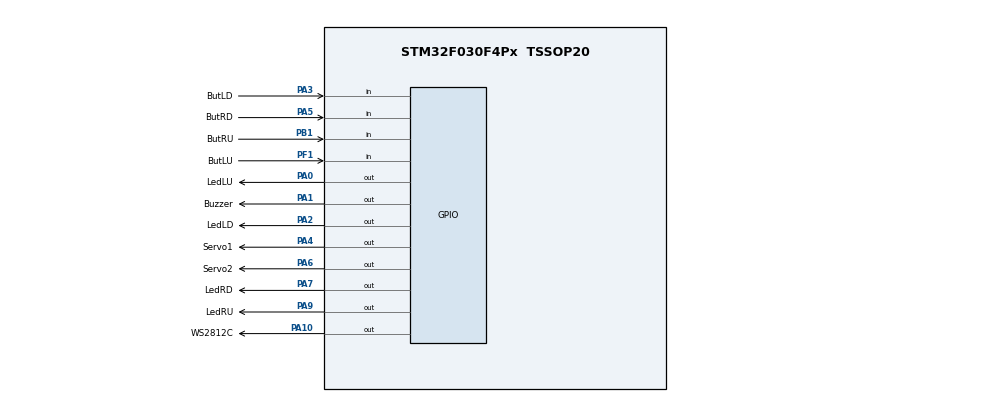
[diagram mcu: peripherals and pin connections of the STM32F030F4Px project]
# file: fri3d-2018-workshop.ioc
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Mcu.Family=STM32F0
Mcu.Name=STM32F030F4Px
Mcu.Package=TSSOP20
PA0.GPIO_Label=LedLU
PA0.Signal=GPIO_Output
PA1.GPIO_Label=Buzzer
PA1.Signal=GPIO_Output
PA10.GPIO_Label=WS2812C
PA10.Signal=GPIO_Output
PA13.Mode=Serial_Wire
PA13.Signal=SYS_SWDIO
PA14.Mode=Serial_Wire
PA14.Signal=SYS_SWCLK
PA2.GPIO_Label=LedLD
PA2.Signal=GPIO_Output
PA3.GPIO_Label=ButLD
PA3.GPIO_PuPd=GPIO_PULLUP
PA3.Signal=GPIO_Input
PA4.GPIO_Label=Servo1
PA4.Signal=GPIO_Output
PA5.GPIO_Label=ButRD
PA5.GPIO_PuPd=GPIO_PULLUP
PA5.Signal=GPIO_Input
PA6.GPIO_Label=Servo2
PA6.Signal=GPIO_Output
PA7.GPIO_Label=LedRD
PA7.Signal=GPIO_Output
PA9.GPIO_Label=LedRU
PA9.Signal=GPIO_Output
PB1.GPIO_Label=ButRU
PB1.GPIO_PuPd=GPIO_PULLUP
PB1.Signal=GPIO_Input
PF1-OSC_OUT.GPIO_Label=ButLU
PF1-OSC_OUT.GPIO_PuPd=GPIO_PULLUP
PF1-OSC_OUT.Signal=GPIO_Input
ProjectManager.HeapSize=0x200
ProjectManager.StackSize=0x400
ProjectManager.TargetToolchain=SW4STM32
board=custom

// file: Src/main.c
/**
  ******************************************************************************
  * @file           : main.c
  * @brief          : Main program body
  ******************************************************************************
  ** This notice applies to any and all portions of this file
  * that are not between comment pairs USER CODE BEGIN and
  * USER CODE END. Other portions of this file, whether
  * inserted by the user or by software development tools
  * are owned by their respective copyright owners.
  *
  * COPYRIGHT(c) 2018 STMicroelectronics
  *
  * Redistribution and use in source and binary forms, with or without modification,
  * are permitted provided that the following conditions are met:
  *   1. Redistributions of source code must retain the above copyright notice,
  *      this list of conditions and the following disclaimer.
  *   2. Redistributions in binary form must reproduce the above copyright notice,
  *      this list of conditions and the following disclaimer in the documentation
  *      and/or other materials provided with the distribution.
  *   3. Neither the name of STMicroelectronics nor the names of its contributors
  *      may be used to endorse or promote products derived from this software
  *      without specific prior written permission.
  *
  * THIS SOFTWARE IS PROVIDED BY THE COPYRIGHT HOLDERS AND CONTRIBUTORS "AS IS"
  * AND ANY EXPRESS OR IMPLIED WARRANTIES, INCLUDING, BUT NOT LIMITED TO, THE
  * IMPLIED WARRANTIES OF MERCHANTABILITY AND FITNESS FOR A PARTICULAR PURPOSE ARE
  * DISCLAIMED. IN NO EVENT SHALL THE COPYRIGHT HOLDER OR CONTRIBUTORS BE LIABLE
  * FOR ANY DIRECT, INDIRECT, INCIDENTAL, SPECIAL, EXEMPLARY, OR CONSEQUENTIAL
  * DAMAGES (INCLUDING, BUT NOT LIMITED TO, PROCUREMENT OF SUBSTITUTE GOODS OR
  * SERVICES; LOSS OF USE, DATA, OR PROFITS; OR BUSINESS INTERRUPTION) HOWEVER
  * CAUSED AND ON ANY THEORY OF LIABILITY, WHETHER IN CONTRACT, STRICT LIABILITY,
  * OR TORT (INCLUDING NEGLIGENCE OR OTHERWISE) ARISING IN ANY WAY OUT OF THE USE
  * OF THIS SOFTWARE, EVEN IF ADVISED OF THE POSSIBILITY OF SUCH DAMAGE.
  *
  ******************************************************************************
  */
#include "main.h"
#include "stm32f0xx_hal.h"

/* USER CODE BEGIN PV */
/* Private variables ---------------------------------------------------------*/

/* USER CODE END PV */

void SystemClock_Config(void);
static void MX_GPIO_Init(void);

/* USER CODE BEGIN PFP */
/* Private function prototypes -----------------------------------------------*/

/* USER CODE END PFP */

int main(void)
{

  /* MCU Configuration----------------------------------------------------------*/

  /* Reset of all peripherals, Initializes the Flash interface and the Systick. */
  HAL_Init();

  /* Configure the system clock */
  SystemClock_Config();

  /* Initialize all configured peripherals */
  MX_GPIO_Init();

  /* Infinite loop */
  while (1)
  {

  /* USER CODE BEGIN 3 */
	  volatile uint32_t nextUpdate = 0;
	  /*
	   * LU: A0
	   * LD: A2
	   * RD: A7
	   * RU: A9
	   */
	  /*const uint32_t patroon[] = {0x02840001, 0x02810004, 0x02050080, 0x00850200};

	  if (HAL_GetTick() >= nextUpdate) {
		  nextUpdate += 100;
		  static uint8_t currframe = 0;
		  *(((volatile unsigned long *)LedLD_GPIO_Port)+0x6U) = patroon[currframe];
		  if (++currframe >= 3) {
			currframe = 0;
		}
	  }*/
	  HAL_GPIO_WritePin(LedLU_GPIO_Port, LedLU_Pin, 0);
	  HAL_GPIO_WritePin(LedRU_GPIO_Port, LedRU_Pin, 1);
	  HAL_Delay(300);
	  HAL_GPIO_WritePin(LedLD_GPIO_Port, LedLD_Pin, 0);
	  HAL_GPIO_WritePin(LedLU_GPIO_Port, LedLU_Pin, 1);
	  HAL_Delay(300);
	  HAL_GPIO_WritePin(LedRD_GPIO_Port, LedRD_Pin, 0);
	  HAL_GPIO_WritePin(LedLD_GPIO_Port, LedLD_Pin, 1);
	  HAL_Delay(300);
	  HAL_GPIO_WritePin(LedRU_GPIO_Port, LedRU_Pin, 0);
	  HAL_GPIO_WritePin(LedRD_GPIO_Port, LedRD_Pin, 1);
	  HAL_Delay(300);

  }
  /* USER CODE END 3 */

}

void SystemClock_Config(void)
{

  RCC_OscInitTypeDef RCC_OscInitStruct;
  RCC_ClkInitTypeDef RCC_ClkInitStruct;

    /**Initializes the CPU, AHB and APB busses clocks
    */
  RCC_OscInitStruct.OscillatorType = RCC_OSCILLATORTYPE_HSI;
  RCC_OscInitStruct.HSIState = RCC_HSI_ON;
  RCC_OscInitStruct.HSICalibrationValue = 16;
  RCC_OscInitStruct.PLL.PLLState = RCC_PLL_NONE;
  if (HAL_RCC_OscConfig(&RCC_OscInitStruct) != HAL_OK)
  {
    _Error_Handler(__FILE__, __LINE__);
  }

    /**Initializes the CPU, AHB and APB busses clocks
    */
  RCC_ClkInitStruct.ClockType = RCC_CLOCKTYPE_HCLK|RCC_CLOCKTYPE_SYSCLK
                              |RCC_CLOCKTYPE_PCLK1;
  RCC_ClkInitStruct.SYSCLKSource = RCC_SYSCLKSOURCE_HSI;
  RCC_ClkInitStruct.AHBCLKDivider = RCC_SYSCLK_DIV1;
  RCC_ClkInitStruct.APB1CLKDivider = RCC_HCLK_DIV1;

  if (HAL_RCC_ClockConfig(&RCC_ClkInitStruct, FLASH_LATENCY_0) != HAL_OK)
  {
    _Error_Handler(__FILE__, __LINE__);
  }

    /**Configure the Systick interrupt time
    */
  HAL_SYSTICK_Config(HAL_RCC_GetHCLKFreq()/1000);

    /**Configure the Systick
    */
  HAL_SYSTICK_CLKSourceConfig(SYSTICK_CLKSOURCE_HCLK);

  /* SysTick_IRQn interrupt configuration */
  HAL_NVIC_SetPriority(SysTick_IRQn, 0, 0);
}

/** Configure pins as
        * Analog
        * Input
        * Output
        * EVENT_OUT
        * EXTI
*/
static void MX_GPIO_Init(void)
{

  GPIO_InitTypeDef GPIO_InitStruct;

  /* GPIO Ports Clock Enable */
  __HAL_RCC_GPIOF_CLK_ENABLE();
  __HAL_RCC_GPIOA_CLK_ENABLE();
  __HAL_RCC_GPIOB_CLK_ENABLE();

  /*Configure GPIO pin Output Level */
  HAL_GPIO_WritePin(GPIOA, LedLU_Pin|Buzzer_Pin|LedLD_Pin|Servo1_Pin
                          |Servo2_Pin|LedRD_Pin|LedRU_Pin|WS2812C_Pin, GPIO_PIN_RESET);

  /*Configure GPIO pin : ButLU_Pin */
  GPIO_InitStruct.Pin = ButLU_Pin;
  GPIO_InitStruct.Mode = GPIO_MODE_INPUT;
  GPIO_InitStruct.Pull = GPIO_PULLUP;
  HAL_GPIO_Init(ButLU_GPIO_Port, &GPIO_InitStruct);

  /*Configure GPIO pins : LedLU_Pin Buzzer_Pin LedLD_Pin Servo1_Pin
                           Servo2_Pin LedRD_Pin LedRU_Pin WS2812C_Pin */
  GPIO_InitStruct.Pin = LedLU_Pin|Buzzer_Pin|LedLD_Pin|Servo1_Pin
                          |Servo2_Pin|LedRD_Pin|LedRU_Pin|WS2812C_Pin;
  GPIO_InitStruct.Mode = GPIO_MODE_OUTPUT_PP;
  GPIO_InitStruct.Pull = GPIO_NOPULL;
  GPIO_InitStruct.Speed = GPIO_SPEED_FREQ_LOW;
  HAL_GPIO_Init(GPIOA, &GPIO_InitStruct);

  /*Configure GPIO pins : ButLD_Pin ButRD_Pin */
  GPIO_InitStruct.Pin = ButLD_Pin|ButRD_Pin;
  GPIO_InitStruct.Mode = GPIO_MODE_INPUT;
  GPIO_InitStruct.Pull = GPIO_PULLUP;
  HAL_GPIO_Init(GPIOA, &GPIO_InitStruct);

  /*Configure GPIO pin : ButRU_Pin */
  GPIO_InitStruct.Pin = ButRU_Pin;
  GPIO_InitStruct.Mode = GPIO_MODE_INPUT;
  GPIO_InitStruct.Pull = GPIO_PULLUP;
  HAL_GPIO_Init(ButRU_GPIO_Port, &GPIO_InitStruct);

}

void _Error_Handler(char *file, int line)
{
  while(1)
  {
  }
}

/************************ (C) COPYRIGHT STMicroelectronics *****END OF FILE****/
